# MK22F10 register map
File version: 1.6
Registers are 32-bit, read-write, reset 0x0 unless marked. A register's access mark holds for its fields unless they carry their own. Offsets are from the block's base; [hi:lo] are bit positions; {n}, {i} and the like mark numbered series.

## PMC — Power Management Controller
Base 0x4007D000; register names take the prefix PMC_
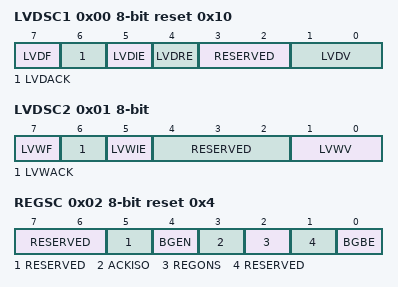
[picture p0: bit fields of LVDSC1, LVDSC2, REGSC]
0x00 LVDSC1 8-bit reset 0x10 — Low Voltage Detect Status And Control 1 register
  [7] LVDF ro — Low-Voltage Detect Flag
    0=Low-voltage event not detected; 1=Low-voltage event detected
  [6] LVDACK wo — Low-Voltage Detect Acknowledge
  [5] LVDIE — Low-Voltage Detect Interrupt Enable
    0=Hardware interrupt disabled (use polling); 1=Request a hardware interrupt when LVDF = 1
  [4] LVDRE — Low-Voltage Detect Reset Enable
    0=LVDF does not generate hardware resets; 1=Force an MCU reset when LVDF = 1
  [3:2] RESERVED ro
  [1:0] LVDV — Low-Voltage Detect Voltage Select
    0=Low trip point selected (V LVD = V LVDL ); 1=High trip point selected (V LVD = V LVDH )
0x01 LVDSC2 8-bit — Low Voltage Detect Status And Control 2 register
  [7] LVWF ro — Low-Voltage Warning Flag
    0=Low-voltage warning event not detected; 1=Low-voltage warning event detected
  [6] LVWACK wo — Low-Voltage Warning Acknowledge
  [5] LVWIE — Low-Voltage Warning Interrupt Enable
    0=Hardware interrupt disabled (use polling); 1=Request a hardware interrupt when LVWF = 1
  [4:2] RESERVED ro
  [1:0] LVWV — Low-Voltage Warning Voltage Select
    0=Low trip point selected (VLVW = VLVW1); 1=Mid 1 trip point selected (VLVW = VLVW2); 2=Mid 2 trip point selected (VLVW = VLVW3); 3=High trip point selected (VLVW = VLVW4)
0x02 REGSC 8-bit reset 0x4 — Regulator Status And Control register
  [7:6] RESERVED ro
  [5] RESERVED
  [4] BGEN — Bandgap Enable In VLPx Operation
    0=Bandgap voltage reference is disabled in VLPx , LLS , and VLLSx modes; 1=Bandgap voltage reference is enabled in VLPx , LLS , and VLLSx modes
  [3] ACKISO — Acknowledge Isolation
    0=Peripherals and I/O pads are in normal run state; 1=Certain peripherals and I/O pads are in an isolated and latched state
  [2] REGONS ro — Regulator In Run Regulation Status
    0=Regulator is in stop regulation or in transition to/from it; 1=Regulator is in run regulation
  [1] RESERVED
  [0] BGBE — Bandgap Buffer Enable
    0=Bandgap buffer not enabled; 1=Bandgap buffer enabled

## SMC — System Mode Controller
Base 0x4007E000; register names take the prefix SMC_
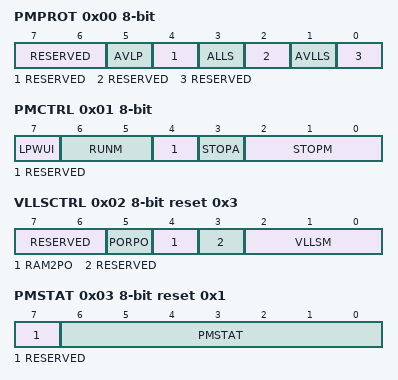
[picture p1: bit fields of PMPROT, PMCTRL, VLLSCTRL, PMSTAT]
0x00 PMPROT 8-bit — Power Mode Protection register
  [7:6] RESERVED ro
  [5] AVLP — Allow Very-Low-Power Modes
    0=VLPR, VLPW and VLPS are not allowed; 1=VLPR, VLPW and VLPS are allowed
  [4] RESERVED ro
  [3] ALLS — Allow Low-Leakage Stop Mode
    0=LLS is not allowed; 1=LLS is allowed
  [2] RESERVED ro
  [1] AVLLS — Allow Very-Low-Leakage Stop Mode
    0=Any VLLSx mode is not allowed; 1=Any VLLSx mode is allowed
  [0] RESERVED ro
0x01 PMCTRL 8-bit — Power Mode Control register
  [7] LPWUI — Low-Power Wake Up On Interrupt
    0=The system remains in a VLP mode on an interrupt; 1=The system exits to Normal RUN mode on an interrupt
  [6:5] RUNM — Run Mode Control
    0=Normal Run mode (RUN); 2=Very-Low-Power Run mode (VLPR)
  [4] RESERVED ro
  [3] STOPA ro — Stop Aborted
    0=The previous stop mode entry was successsful; 1=The previous stop mode entry was aborted
  [2:0] STOPM — Stop Mode Control
    0=Normal Stop (STOP); 2=Very-Low-Power Stop (VLPS); 3=Low-Leakage Stop (LLS); 4=Very-Low-Leakage Stop (VLLSx); 6=Reseved
0x02 VLLSCTRL 8-bit reset 0x3 — VLLS Control register
  [7:6] RESERVED ro
  [5] PORPO — POR Power Option
    0=POR detect circuit is enabled in VLLS0; 1=POR detect circuit is disabled in VLLS0
  [4] RAM2PO — RAM2 Power Option
    0=RAM2 not powered in VLLS2; 1=RAM2 powered in VLLS2
  [3] RESERVED ro
  [2:0] VLLSM — VLLS Mode Control
    {v}=VLLS{v} (v=0..3)
0x03 PMSTAT 8-bit ro reset 0x1 — Power Mode Status register
  [7] RESERVED, [6:0] PMSTAT

## RCM — Reset Control Module
Base 0x4007F000; register names take the prefix RCM_
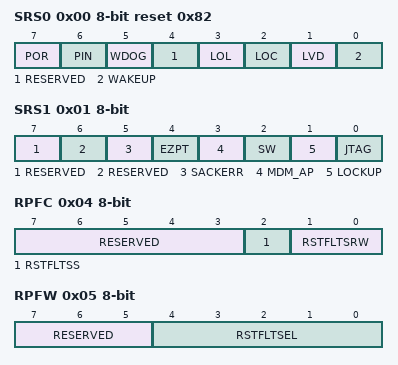
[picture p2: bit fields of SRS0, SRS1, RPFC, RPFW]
0x00 SRS0 8-bit ro reset 0x82 — System Reset Status Register 0
  [7] POR — Power-On Reset
    0=Reset not caused by POR; 1=Reset caused by POR
  [6] PIN — External Reset Pin
    0=Reset not caused by external reset pin; 1=Reset caused by external reset pin
  [5] WDOG — Watchdog
    0=Reset not caused by watchdog timeout; 1=Reset caused by watchdog timeout
  [4] RESERVED
  [3] LOL — Loss-of-Lock Reset
    0=Reset not caused by a loss of lock in the PLL; 1=Reset caused by a loss of lock in the PLL
  [2] LOC — Loss-of-Clock Reset
    0=Reset not caused by a loss of external clock; 1=Reset caused by a loss of external clock
  [1] LVD — Low-Voltage Detect Reset
    0=Reset not caused by LVD trip or POR; 1=Reset caused by LVD trip or POR
  [0] WAKEUP — Low Leakage Wakeup Reset
    0=Reset not caused by LLWU module wakeup source; 1=Reset caused by LLWU module wakeup source
0x01 SRS1 8-bit ro — System Reset Status Register 1
  [7] RESERVED
  [6] RESERVED
  [5] SACKERR — Stop Mode Acknowledge Error Reset
    0=Reset not caused by peripheral failure to acknowledge attempt to enter stop mode; 1=Reset caused by peripheral failure to acknowledge attempt to enter stop mode
  [4] EZPT — EzPort Reset
    0=Reset not caused by EzPort receiving the RESET command while the device is in EzPort mode; 1=Reset caused by EzPort receiving the RESET command while the device is in EzPort mode
  [3] MDM_AP — MDM-AP System Reset Request
    0=Reset not caused by host debugger system setting of the System Reset Request bit; 1=Reset caused by host debugger system setting of the System Reset Request bit
  [2] SW — Software
    0=Reset not caused by software setting of SYSRESETREQ bit; 1=Reset caused by software setting of SYSRESETREQ bit
  [1] LOCKUP — Core Lockup
    0=Reset not caused by core LOCKUP event; 1=Reset caused by core LOCKUP event
  [0] JTAG — JTAG Generated Reset
    0=Reset not caused by JTAG; 1=Reset caused by JTAG
0x04 RPFC 8-bit — Reset Pin Filter Control register
  [7:3] RESERVED ro
  [2] RSTFLTSS — Reset Pin Filter Select in Stop Mode
    0=All filtering disabled; 1=LPO clock filter enabled
  [1:0] RSTFLTSRW — Reset Pin Filter Select in Run and Wait Modes
    0=All filtering disabled; 1=Bus clock filter enabled for normal operation; 2=LPO clock filter enabled for normal operation
0x05 RPFW 8-bit — Reset Pin Filter Width register
  [7:5] RESERVED ro
  [4:0] RSTFLTSEL — Reset Pin Filter Bus Clock Select
    {v}=Bus clock filter count is {v+1} (v=0..31)
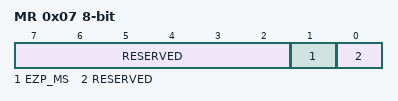
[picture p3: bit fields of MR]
0x07 MR 8-bit ro — Mode Register
  [7:2] RESERVED
  [1] EZP_MS — EZP_MS_B pin state
    0=Pin deasserted (logic 1); 1=Pin asserted (logic 0)
  [0] RESERVED
